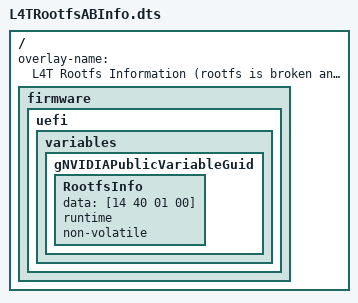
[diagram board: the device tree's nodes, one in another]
/** @file
*
*  Copyright (c) 2022, NVIDIA CORPORATION & AFFILIATES. All rights reserved.
*
*  SPDX-License-Identifier: BSD-2-Clause-Patent
*
**/

/dts-v1/;
/plugin/;

/ {
	overlay-name = "L4T Rootfs Information (rootfs is broken and forced into recovery)";

	fragment@0 {
		target-path = "/";
		board_config {
			sw-modules = "uefi";
		};

		__overlay__ {
			firmware {
				uefi {
					variables {
						gNVIDIAPublicVariableGuid {
							RootfsInfo {
								data = [14 40 01 00];
								runtime;
								non-volatile;
							};
						};
					};
				};
			};
		};
	};
};
